# NUC1261AE_v1 register map
File version: 1.0
Registers are 32-bit, read-write, reset 0x0 unless marked. A register's access mark holds for its fields unless they carry their own. Offsets are from the block's base; [hi:lo] are bit positions; {n}, {i} and the like mark numbered series.

## RTC — RTC Register Map
Base 0x40008000
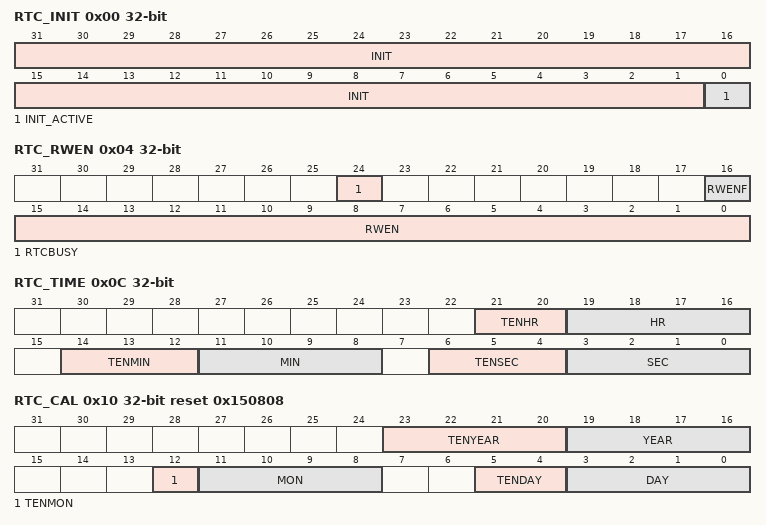
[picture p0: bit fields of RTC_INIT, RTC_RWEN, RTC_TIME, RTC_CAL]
0x00 RTC_INIT — RTC Initiation Register
  [31:1] INIT — RTC Initiation. When RTC block is first powered on, RTC is at reset state. User has to write a special number 0xA5EB1357 to INIT to make RTC leaving reset state. Once the INIT is written as 0xA5EB1357 the RTC will be at normal active state permanently. The INIT[31:1] is a write-only field and read value will be always 0.
  [0] INIT_ACTIVE ro — RTC Active Status (Read Only)
    0=RTC is at reset state; 1=RTC is at normal active state
0x04 RTC_RWEN — RTC Access Enable Register
  [24] RTCBUSY — RTC Write Busy Flag. This bit indicates RTC registers are writable or not. Note: RTCBUSY falg will be set when execute write RTC register command exceed 6 times within 1120 PCLK cycles.Reserved.
    0=RTC register write Disabled; 1=RTC register write Enabled
  [16] RWENF ro — RTC Register Access Enable Bit (Read Only). Note1: This bit will be set after RWEN is load a 0xA965, and be cleared automatically after 1024 RTC clocks expired. Note2: RWENF will be mask to 0 during RTCBUSY is 1, and first turn on RTCCKEN (CLK_APBCLK[1]) also.
    0=RTC register read/write Disabled; 1=RTC register read/write Enabled
  [15:0] RWEN wo — RTC Register Access Enable Password (Write Only). Writing 0xA965 to this field will enable RTC register access period and keep 1024 RTC clocks. Note: Writing others vaule will clear RWENF and disable RTC register access function immediately.
0x08 RTC_FREQADJ reset 0x200000 — RTC Frequency Compensation Register
  [21:0] FREQADJ — Frequency Compensation Value. User has to get actual clock frequency of LXT, LXT frequency. Note: This formula is suitable only when RTCSEL (CLK_CLKSEL2[18]) is 0, RTC clock source is from LXT.Reserved.
0x0C RTC_TIME — RTC Time Loading Register
  [21:20] TENHR — 10-hour Time Digit (0~2). Note: When RTC runs as 12-hour time scale mode, RTC_TIME[21] (the high bit of TENHR[1:0]) means AM/PM indication, RTC_TIME[21] is 0 means AM hour and RTC_TIME[21] is 1 means PM hour.
  [19:16] HR — 1-Hour Time Digit (0~9)
  [14:12] TENMIN — 10-Min Time Digit (0~5)
  [11:8] MIN — 1-Min Time Digit (0~9)
  [6:4] TENSEC — 10-Sec Time Digit (0~5)
  [3:0] SEC — 1-Sec Time Digit (0~9)
0x10 RTC_CAL reset 0x150808 — RTC Calendar Loading Register
  [23:20] TENYEAR — 10-Year Calendar Digit (0~9)
  [19:16] YEAR — 1-Year Calendar Digit (0~9)
  [12] TENMON — 10-Month Calendar Digit (0~1)
  [11:8] MON — 1-Month Calendar Digit (0~9)
  [5:4] TENDAY — 10-Day Calendar Digit (0~3)
  [3:0] DAY — 1-Day Calendar Digit (0~9)
0x14 RTC_CLKFMT reset 0x1 — RTC Time Scale Selection Register
  [0] _24HEN — 24-hour / 12-hour Time Scale Selection. Indicates that RTC_TIME and RTC_TALM register are in 24-hour time scale or 12-hour time scale
    0=12-hour time scale with AM and PM indication selected; 1=24-hour time scale selected
0x18 RTC_WEEKDAY reset 0x6 — RTC Day of the Week Register
  [2:0] WEEKDAY — Day of the Week Register. Note: RTC will not check WEEKDAY setting with RTC_CAL is reasonable or not.
    0=Sunday; 1=Monday; 2=Tuesday; 3=Wednesday; 4=Thursday; 5=Friday; 6=Saturday
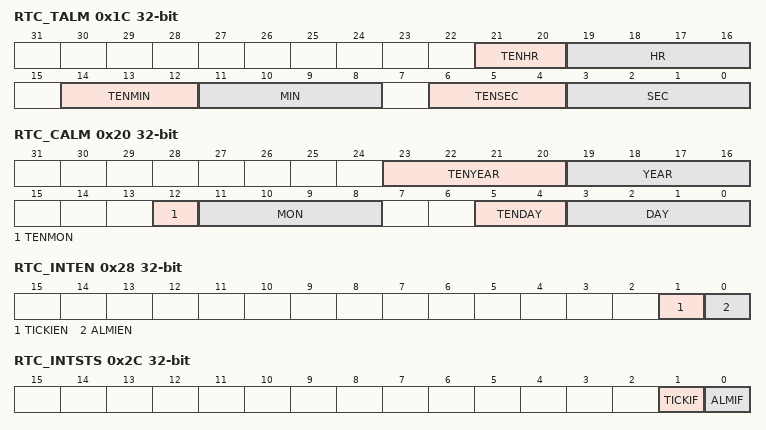
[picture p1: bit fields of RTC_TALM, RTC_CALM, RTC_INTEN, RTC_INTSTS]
0x1C RTC_TALM — RTC Time Alarm Register
  [21:20] TENHR — 10-Hour Time Digit of Alarm Setting (0~2)When RTC runs as 12-hour time scale mode, RTC_TIME[21] (the high bit of TENHR[1:0]) means AM/PM indication (If RTC_TIME[21] is 1, it indicates PM time message.)
  [19:16] HR — 1-Hour Time Digit of Alarm Setting (0~9)
  [14:12] TENMIN — 10-Min Time Digit of Alarm Setting (0~5)
  [11:8] MIN — 1-Min Time Digit of Alarm Setting (0~9)
  [6:4] TENSEC — 10-Sec Time Digit of Alarm Setting (0~5)
  [3:0] SEC — 1-Sec Time Digit of Alarm Setting (0~9)
0x20 RTC_CALM — RTC Calendar Alarm Register
  [23:20] TENYEAR — 10-Year Calendar Digit of Alarm Setting (0~9)
  [19:16] YEAR — 1-Year Calendar Digit of Alarm Setting (0~9)
  [12] TENMON — 10-Month Calendar Digit of Alarm Setting (0~1)
  [11:8] MON — 1-Month Calendar Digit of Alarm Setting (0~9)
  [5:4] TENDAY — 10-Day Calendar Digit of Alarm Setting (0~3)
  [3:0] DAY — 1-Day Calendar Digit of Alarm Setting (0~9)
0x24 RTC_LEAPYEAR ro — RTC Leap Year Indicaton Register
  [0] LEAPYEAR — Leap Year Indication Register (Read Only)
    0=This year is not a leap year; 1=This year is leap year
0x28 RTC_INTEN — RTC Interrupt Enable Register
  [1] TICKIEN — Time Tick Interrupt Enable Bit
    0=RTC time tick interrupt Disabled; 1=RTC time tick interrupt Enabled
  [0] ALMIEN — Alarm Interrupt Enable Bit
    0=RTC alarm interrupt Disabled; 1=RTC alarm interrupt Enabled
0x2C RTC_INTSTS — RTC Interrupt Status Register
  [1] TICKIF — RTC Time Tick Interrupt Flag. When RTC time tick event happened, TICKIF will be set to 1 and a time tick interrupt signal will be generated if TICKIEN (RTC_INTEN[1]) is enabled. Chip will also be waken up when time tick interrupt signal occurred if chip is running at Power-down mode. Note: Writing 1 to clear this bit.
    0=Tick condition did not occur; 1=Tick condition occurred
  [0] ALMIF — RTC Alarm Interrupt Flag. When current RTC counter in RTC_TIME and RTC_CAL are matched RTC alarm settings in RTC_TALM and RTC_CALM, ALMIF will be set to 1 and an alarm interrupt signal will be generated if ALMIEN (RTC_INTEN[0]) is enabled. Chip will also be waken up when alarm interrupt signal occurred if chip is running at Power-down mode. Note: Writing 1 to clear this bit.
    0=Alarm condition is not matched; 1=Alarm condition is matched
0x30 RTC_TICK — RTC Time Tick Register
  [2:0] TICK — Time Tick Register. These bits are used to select RTC time tick period for periodic time tick interrupt request.
    0=Time tick is 1 second; 1=Time tick is 1/2 second; 2=Time tick is 1/4 second; 3=Time tick is 1/8 second; 4=Time tick is 1/16 second; 5=Time tick is 1/32 second; 6=Time tick is 1/64 second; 7=Time tick is 1/128 second
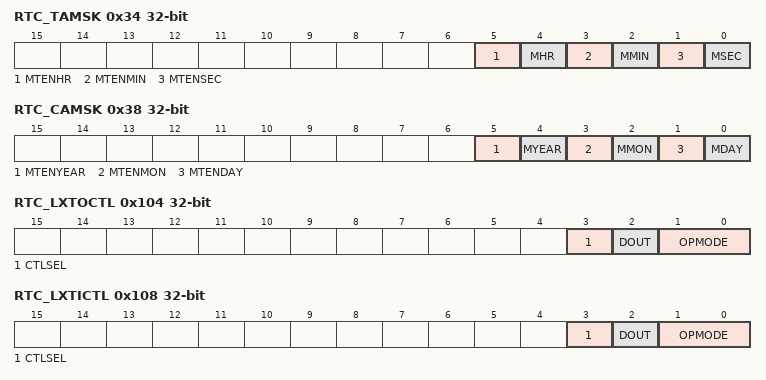
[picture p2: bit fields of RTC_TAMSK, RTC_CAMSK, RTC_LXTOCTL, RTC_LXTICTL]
0x34 RTC_TAMSK — RTC Time Alarm Mask Register
  [5] MTENHR — Mask 10-hour Time Digit of Alarm Setting (0~2). Note: MTENHR function is only for 24-hour time scale mode.
  [4] MHR — Mask 1-hour Time Digit of Alarm Setting (0~9). Note: MHR function is only for 24-hour time scale mode.
  [3] MTENMIN — Mask 10-Min Time Digit of alarm setting (0~5)
  [2] MMIN — Mask 1-Min Time Digit of alarm setting (0~9)
  [1] MTENSEC — Mask 10-Sec Time Digit of alarm setting (0~5)
  [0] MSEC — Mask 1-Sec Time Digit of alarm setting (0~9)
0x38 RTC_CAMSK — RTC Calendar Alarm Mask Register
  [5] MTENYEAR — Mask 10-Year Calendar Digit of alarm setting (0~9)
  [4] MYEAR — Mask 1-Year Calendar Digit of alarm setting (0~9)
  [3] MTENMON — Mask 10-Month Calendar Digit of alarm setting (0~1)
  [2] MMON — Mask 1-Month Calendar Digit of alarm setting (0~9)
  [1] MTENDAY — Mask 10-Day Calendar Digit of alarm setting (0~3)
  [0] MDAY — Mask 1-Day Calendar Digit of alarm setting (0~9)
0x100 RTC_LXTCTL reset 0xE — RTC 32 KHz Oscillator Control Register
  [3:1] GAIN — Oscillator Gain Option. User can select oscillator gain according to crystal external loading and operating temperature range. The larger gain value corresponding to stronger driving capability and higher power consumption.
    {v}=L{v} mode (v=0..6); 7=L7 mode (Default)
0x104 RTC_LXTOCTL — RTC X32KO Pin Control Register
  [3] CTLSEL — I/O Pin State Backup Selection. When low speed 32 kHz oscillator (LXT) is disabled, X32KO pin can be used as GPIO PF.0 function. User can program CTLSEL to decide X32KO (PF.0) I/O function is controlled by system power domain GPIO module or VBAT power domain RTC_LXTOCTL register. Note: CTLSEL will be set to 1 automatically by hardware when system power is turned off and RTC is at normal active state, ACTIVE (RTC_INIT[0]) is 1.
    0=X32KO (PF.0) pin I/O function is controlled by GPIO module; 1=X32KO (PF.0) pin I/O function is controlled by OPMODE and DOUT in RTC_LXTOCT at VBAT power domain
  [2] DOUT — I/O Pin Output Data
    0=X32KO (PF.0) will drive low in output mode; 1=X32KO (PF.0) will drive high in output mode
  [1:0] OPMODE — I/O Pin Operation Mode
    0=X32KO (PF.0) is in Input mode without pull-up resistor; 1=X32KO (PF.0) is in Push-pull output mode; 2=X32KO (PF.0) is in Open-drain output mode; 3=X32KO (PF.0) is in Input mode with pull-up resistor
0x108 RTC_LXTICTL — RTC X32KI Pin Control Register
  [3] CTLSEL — I/O Pin State Backup Selection. When low speed 32 kHz oscillator (LXT) is disabled, X32KO pin can be used as GPIO PF.1 function. User can program CTLSEL to decide X32KI (PF.1) I/O function is controlled by system power domain GPIO module or VBAT power domain RTC_LXTICTL register. Note: CTLSEL will be set to 1 automatically by hardware when system power is turned off and RTC is at normal active state, ACTIVE (RTC_INIT[0]) is 1.
    0=X32KI (PF.1) pin I/O function is controlled by GPIO module; 1=X32KI (PF.1) pin I/O function is controlled by OPMODE and DOUT in RTC_LXTICTL at VBAT power domain
  [2] DOUT — IO Pin Output Data
    0=X32KI (PF.1) will drive low in output mode; 1=X32KI (PF.1) will drive high in output mode
  [1:0] OPMODE — I/O Pin Operation Mode
    0=X32KI (PF.1) is in Input mode without pull-up resistor; 1=X32KI (PF.1) is in Push-pull output mode; 2=X32KI (PF.1) is in Open-drain output mode; 3=X32KI (PF.1) is in Input mode with pull-up resistor
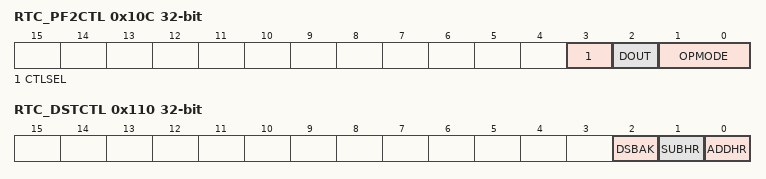
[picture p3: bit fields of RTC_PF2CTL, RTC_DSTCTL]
0x10C RTC_PF2CTL — RTC PF.2 Pin Control Register
  [3] CTLSEL — I/O Pin State Backup Selection. User can program CTLSEL to decide GPIO PF.2 I/O function is controlled by system power domain GPIO module or VBAT power domain RTC_LXTICTL register. Note: CTLSEL will be set to 1 automatically by hardware when system power is turned off and RTC is at normal active state, ACTIVE (RTC_INIT[0]) is 1.
    0=GPIO PF.2 pin I/O function is controlled by GPIO module; 1=GPIO PF.2 pin I/O function is controlled by OPMODE and DOUT in RTC_PF2CTL at VBAT power domain
  [2] DOUT — I/O Pin Output Data
    0=GPIO PF.2 will drive low in output mode; 1=GPIO PF.2 will drive high in output mode
  [1:0] OPMODE — I/O Pin Operation Mode
    0=PF.2 is in Input mode without pull-up resistor; 1=PF.2 is in Push-pull output mode; 2=PF.2 is in Open-drain output mode; 3=PF.2 is in Input mode with pull-up resistor
0x110 RTC_DSTCTL — RTC Daylight Saving Time Control Register
  [2] DSBAK — Daylight Saving Back
    0=Daylight Saving Time function is not performed; 1=Daylight Saving Time function is performed
  [1] SUBHR — Subtract 1 Hour
    0=No effect; 1=Indicates RTC hour digit has been subtracted one hour for winter time change
  [0] ADDHR — Add 1 Hour
    0=No effect; 1=Indicates RTC hour digit has been added one hour for summer time change
